# STM32C071xx register map
File version: 1.0
Registers are 32-bit, read-write, reset 0x0 unless marked. A register's access mark holds for its fields unless they carry their own. Offsets are from the block's base; [hi:lo] are bit positions; {n}, {i} and the like mark numbered series.

## RCC — Reset and Clock Control
Base 0x40021000
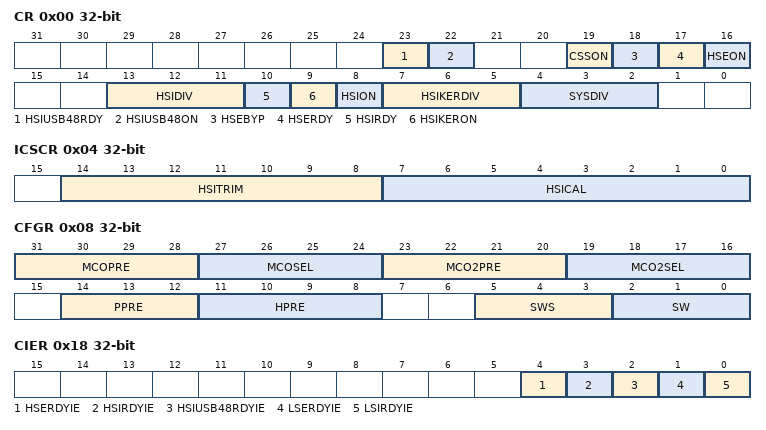
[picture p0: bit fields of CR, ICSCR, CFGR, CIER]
0x00 CR — RCC Clock Sources Control Register
  [23] HSIUSB48RDY — HSI USB 48 clock ready
  [22] HSIUSB48ON — HSI USB 48 clock enable
  [19] CSSON — HSE Clock Security System enable
  [18] HSEBYP — External High Speed clock Bypass
  [17] HSERDY — External High Speed clock ready
  [16] HSEON — External High Speed clock enable
  [13:11] HSIDIV — HSIDIV[13:11] Internal High Speed clock division factor
    0=DIV_1 (HSI not divided); 1=DIV_2 (HSI divided by 2); 2=DIV_4 (HSI divided by 4); 3=DIV_8 (HSI divided by 8); 4=DIV_16 (HSI divided by 16); 5=DIV_32 (HSI divided by 32); 6=DIV_64 (HSI divided by 64); 7=DIV_128 (HSI divided by 128)
  [10] HSIRDY — Internal High Speed clock ready flag
  [9] HSIKERON — Internal High Speed clock enable for some IPs Kernel
  [8] HSION — Internal High Speed clock enable
  [7:5] HSIKERDIV — HSI48 clock division factor for HSI kernel clocks inputs
    0=DIV_1 (HSI kernel not divided); {v}=DIV_{v+1} (HSI kernel divided by {v+1}) (v=1..7)
  [4:2] SYSDIV — Clock division factor for system clock
    0=DIV_1 (SYSCLK not divided); {v}=DIV_{v+1} (SYSCLK divided by {v+1}) (v=1..7)
0x04 ICSCR — RCC Internal Clock Sources Calibration Register
  [14:8] HSITRIM — HSITRIM[14:8] bits
  [7:0] HSICAL — HSICAL[7:0] bits
0x08 CFGR — RCC Regulated Domain Clocks Configuration Register
  [31:28] MCOPRE — MCO prescaler [3:0]
  [27:24] MCOSEL — MCOSEL [3:0] bits (Clock output selection)
  [23:20] MCO2PRE — MCO prescaler [3:0]
  [19:16] MCO2SEL — MCO2SEL [3:0] bits (Clock output selection)
  [14:12] PPRE — PRE1[2:0] bits (APB prescaler)
    0=DIV_1 (HCLK not divided); 4=DIV_2 (HCLK divided by 2); 5=DIV_4 (HCLK divided by 4); 6=DIV_8 (HCLK divided by 8); 7=DIV_16 (HCLK divided by 16)
  [11:8] HPRE — HPRE[3:0] bits (AHB prescaler)
    0=DIV_1 (HCLK not divided); 8=DIV_2 (HCLK divided by 2); 9=DIV_4 (HCLK divided by 4); 10=DIV_8 (HCLK divided by 8); 11=DIV_16 (HCLK divided by 16); 12=DIV_64 (HCLK divided by 64); 13=DIV_128 (HCLK divided by 128); 14=DIV_256 (HCLK divided by 256); 15=DIV_512 (HCLK divided by 512)
  [5:3] SWS — SWS[2:0] bits (System Clock Switch Status)
    0=HSI (HSI used as system clock); 1=HSE (HSE used as system clock); 2=HSIUSB48 (HSIUSB48 used as system clock); 3=LSI (LSI used as system clock); 4=LSE (LSE used as system clock)
  [2:0] SW — SW[2:0] bits (System clock Switch)
    0=HSI (HSI selection as system clock); 1=HSE (HSE selection as system clock); 2=HSIUSB48 (HSIUSB48 selection used as system clock); 3=LSI (LSI selection used as system clock); 4=LSE (LSE selection used as system clock)
0x14 CRRCR — RCC Clock Configuration Register
  [8:0] HSIUSB48CAL — HSIUSB48CAL[8:0] bits
0x18 CIER — RCC Clock Interrupt Enable Register
  [4] HSERDYIE, [3] HSIRDYIE, [2] HSIUSB48RDYIE, [1] LSERDYIE, [0] LSIRDYIE
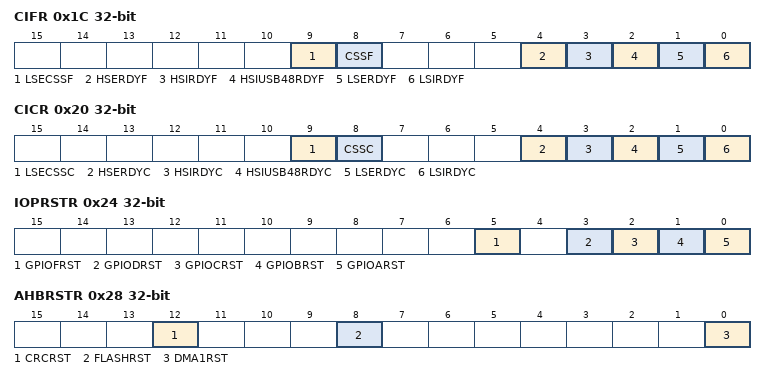
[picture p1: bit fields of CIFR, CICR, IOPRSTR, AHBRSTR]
0x1C CIFR — RCC Clock Interrupt Flag Register
  [9] LSECSSF, [8] CSSF, [4] HSERDYF, [3] HSIRDYF, [2] HSIUSB48RDYF, [1] LSERDYF, [0] LSIRDYF
0x20 CICR — RCC Clock Interrupt Clear Register
  [9] LSECSSC, [8] CSSC, [4] HSERDYC, [3] HSIRDYC, [2] HSIUSB48RDYC, [1] LSERDYC, [0] LSIRDYC
0x24 IOPRSTR — RCC IO port reset register
  [5] GPIOFRST, [3] GPIODRST, [2] GPIOCRST, [1] GPIOBRST, [0] GPIOARST
0x28 AHBRSTR — RCC AHB peripherals reset register
  [12] CRCRST, [8] FLASHRST, [0] DMA1RST
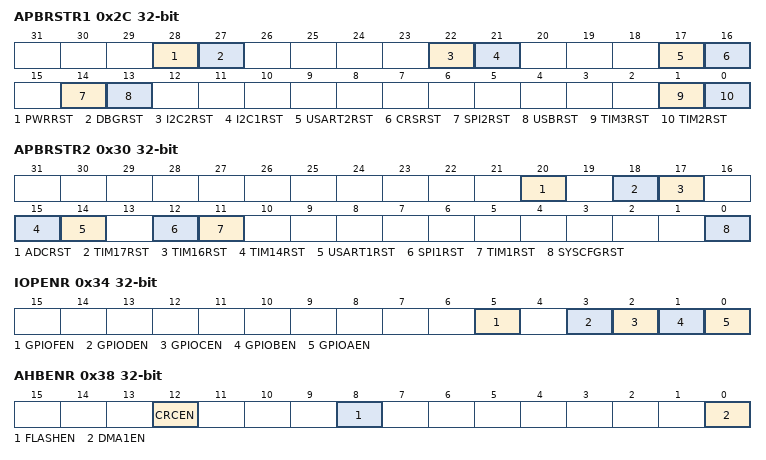
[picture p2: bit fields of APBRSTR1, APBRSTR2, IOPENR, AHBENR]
0x2C APBRSTR1 — RCC APB peripherals reset register 1
  [28] PWRRST, [27] DBGRST, [22] I2C2RST, [21] I2C1RST, [17] USART2RST, [16] CRSRST, [14] SPI2RST, [13] USBRST, [1] TIM3RST, [0] TIM2RST
0x30 APBRSTR2 — RCC APB peripherals reset register 2
  [20] ADCRST, [18] TIM17RST, [17] TIM16RST, [15] TIM14RST, [14] USART1RST, [12] SPI1RST, [11] TIM1RST, [0] SYSCFGRST
0x34 IOPENR — RCC IO port enable register
  [5] GPIOFEN, [3] GPIODEN, [2] GPIOCEN, [1] GPIOBEN, [0] GPIOAEN
0x38 AHBENR — RCC AHB peripherals clock enable register
  [12] CRCEN, [8] FLASHEN, [0] DMA1EN
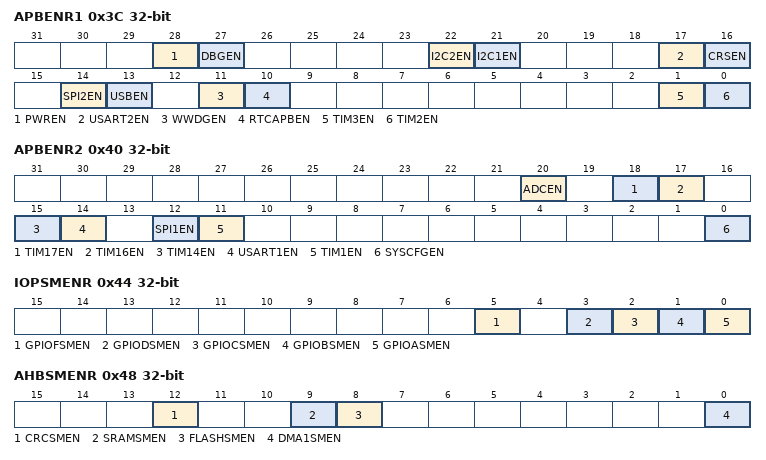
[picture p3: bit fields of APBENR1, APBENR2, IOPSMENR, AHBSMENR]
0x3C APBENR1 — RCC APB peripherals clock enable register1
  [28] PWREN, [27] DBGEN, [22] I2C2EN, [21] I2C1EN, [17] USART2EN, [16] CRSEN, [14] SPI2EN, [13] USBEN, [11] WWDGEN, [10] RTCAPBEN, [1] TIM3EN, [0] TIM2EN
0x40 APBENR2 — RCC APB peripherals clock enable register2
  [20] ADCEN, [18] TIM17EN, [17] TIM16EN, [15] TIM14EN, [14] USART1EN, [12] SPI1EN, [11] TIM1EN, [0] SYSCFGEN
0x44 IOPSMENR — RCC IO port clocks enable in sleep mode register
  [5] GPIOFSMEN, [3] GPIODSMEN, [2] GPIOCSMEN, [1] GPIOBSMEN, [0] GPIOASMEN
0x48 AHBSMENR — RCC AHB peripheral clocks enable in sleep mode register
  [12] CRCSMEN, [9] SRAMSMEN, [8] FLASHSMEN, [0] DMA1SMEN
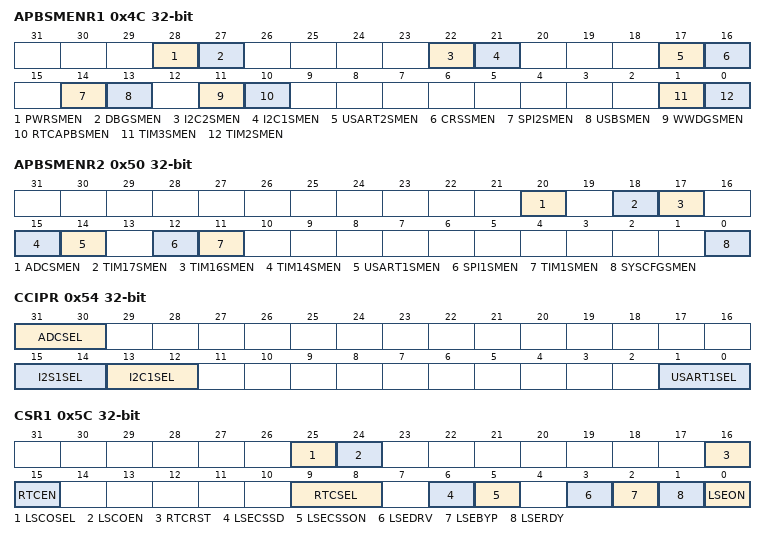
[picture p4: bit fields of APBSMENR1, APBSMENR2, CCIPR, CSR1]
0x4C APBSMENR1 — RCC APB peripheral clocks enable in sleep mode register1
  [28] PWRSMEN, [27] DBGSMEN, [22] I2C2SMEN, [21] I2C1SMEN, [17] USART2SMEN, [16] CRSSMEN, [14] SPI2SMEN, [13] USBSMEN, [11] WWDGSMEN, [10] RTCAPBSMEN, [1] TIM3SMEN, [0] TIM2SMEN
0x50 APBSMENR2 — RCC APB peripheral clocks enable in sleep mode register2
  [20] ADCSMEN, [18] TIM17SMEN, [17] TIM16SMEN, [15] TIM14SMEN, [14] USART1SMEN, [12] SPI1SMEN, [11] TIM1SMEN, [0] SYSCFGSMEN
0x54 CCIPR — RCC Peripherals Independent Clocks Configuration Register
  [31:30] ADCSEL
    0=SYSCLK (SYSCLK used as ADC clock); 2=HSIKER (HSIKER kernel used as ADC clock)
  [15:14] I2S1SEL
    0=SYSCLK (SYSCLK clock used as I2S1 clock source); 3=PIN (External clock used as I2S1 clock source); 2=HSIKER (HSIKER clock used as I2S1 clock source)
  [13:12] I2C1SEL
    0=PCLK1 (PCLK1 clock used as I2C1 clock source); 1=SYSCLK (SYSCLK clock used as I2C1 clock source); 2=HSIKER (HSIKER clock used as I2C1 clock source)
  [1:0] USART1SEL
0x58 CCIPR2 — RCC Peripherals Independent Clocks Configuration Register2
  [12] USBSEL
    0=HSI48 (HSI48 clock used as USB clock source); 1=HSE (HSE clock used as USB clock source)
0x5C CSR1 — RCC Control and status Register 1
  [25] LSCOSEL
    0=LSI (LSI selection for low speed clock); 1=LSE (LSE selection for low speed clock)
  [24] LSCOEN
  [16] RTCRST
  [15] RTCEN
  [9:8] RTCSEL
    0=NONE (No clock used as RTC clock); 1=LSE (LSE oscillator clock used as RTC clock); 2=LSI (LSI oscillator clock used as RTC clock); 3=HSE_DIV32 (HSE oscillator clock divided by 32 used as RTC clock)
  [6] LSECSSD
  [5] LSECSSON
  [3] LSEDRV
    0=MEDIUMHIGH (Xtal mode medium high driving capability); 1=HIGH (Xtal mode higher driving capability)
  [2] LSEBYP
  [1] LSERDY
  [0] LSEON
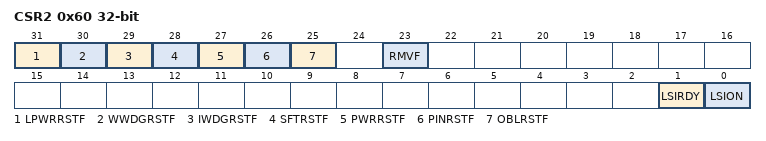
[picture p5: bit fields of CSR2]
0x60 CSR2 — RCC Control and status Register 2
  [31] LPWRRSTF, [30] WWDGRSTF, [29] IWDGRSTF, [28] SFTRSTF, [27] PWRRSTF, [26] PINRSTF, [25] OBLRSTF, [23] RMVF, [1] LSIRDY, [0] LSION
